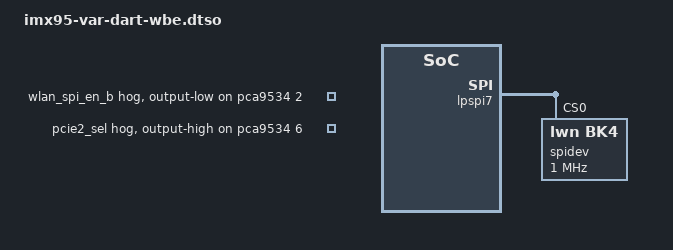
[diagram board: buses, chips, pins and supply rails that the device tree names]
// SPDX-License-Identifier: (GPL-2.0+ OR MIT)
/*
 * Device tree overlay to support the DART-MX95 SoM featuring
 * WiFi/BT chipset with 802.15.4, used on the Sonata-Board
 *
 * Copyright 2026 Variscite Ltd.
 */

/dts-v1/;
/plugin/;

#include <dt-bindings/gpio/gpio.h>

&{/} {
	model = "Variscite DART-MX95 with 802.15.4 on Sonata-Board";
};

/* Disable resistive touch controller on CS0 */
&ads7846 {
	status = "disabled";
};

&lpspi7 {
	#address-cells = <1>;
	#size-cells = <0>;
	pinctrl-0 = <&pinctrl_lpspi7>, <&pinctrl_restouch>;

	/* Enable 802.15.4 SPI device on CS0 */
	spidev@0 {
		reg = <0>;
		compatible = "lwn,bk4";
		spi-max-frequency = <1000000>;
		status = "okay";
	};
};

&pcie2_sel_hog {
	status = "disabled";
};

&pca9534 {
	wlanspi-buf-en {
		gpio-hog;
		gpios = <2 GPIO_ACTIVE_HIGH>;
		output-low;
		line-name = "wlan_spi_en_b";
	};

	pcie2-sel {
		gpio-hog;
		gpios = <6 GPIO_ACTIVE_HIGH>;
		output-high;
		line-name = "pcie2_sel";
	};
};

&pcie1 {
	status = "disabled";
};
